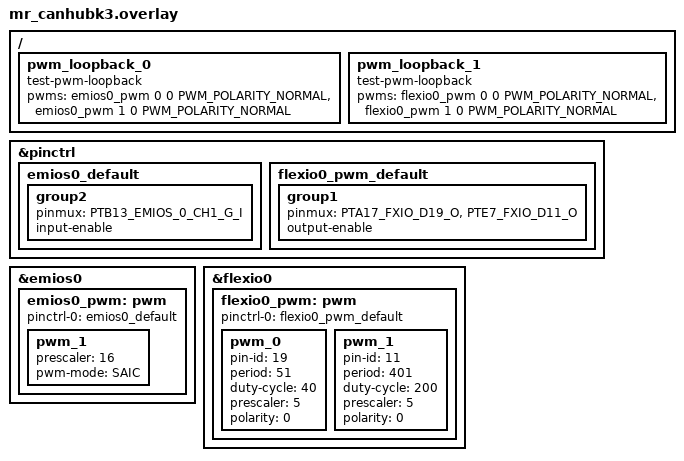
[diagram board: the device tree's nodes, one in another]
/*
 * Copyright 2023 NXP
 *
 * SPDX-License-Identifier: Apache-2.0
 */

#include <zephyr/dt-bindings/pwm/pwm.h>

/ {
	pwm_loopback_0 {
		compatible = "test-pwm-loopback";
		/* Connect P8A pin 3 and P8A pin 6 */
		pwms = <&emios0_pwm 0 0 PWM_POLARITY_NORMAL>,
			<&emios0_pwm 1 0 PWM_POLARITY_NORMAL>;
	};

	pwm_loopback_1 {
		compatible = "test-pwm-loopback";
		pwms = <&flexio0_pwm 0 0 PWM_POLARITY_NORMAL>,
		 <&flexio0_pwm 1 0 PWM_POLARITY_NORMAL>;
 	};
};

&pinctrl {
	emios0_default {
		group2 {
			pinmux = <PTB13_EMIOS_0_CH1_G_I>;
			input-enable;
		};
	};

	flexio0_pwm_default: flexio0_pwm_default {
		group1 {
			pinmux = <PTA17_FXIO_D19_O>, <PTE7_FXIO_D11_O>;
			output-enable;
		};
	};
};

&emios0 {
	emios0_pwm: pwm {
		pinctrl-0 = <&emios0_default>;
		pinctrl-names = "default";
		status = "okay";

		pwm_1 {
			/delete-property/ period;
			/delete-property/ polarity;
			/delete-property/ duty-cycle;
			prescaler = <16>;
			pwm-mode = "SAIC";
		};
	};
};

&flexio0 {
	status = "okay";

	flexio0_pwm: pwm {
		pinctrl-0 = <&flexio0_pwm_default>;
		pinctrl-names = "default";
		status = "okay";

		pwm_0 {
			pin-id = <19>;
			period = <51>;
			duty-cycle = <40>;
			prescaler = <5>;
			polarity = <0>;
		};
	
		pwm_1 {
			pin-id = <11>;
			period = <401>;
			duty-cycle = <200>;
			prescaler = <5>;
			polarity = <0>;
		};
	};
};
